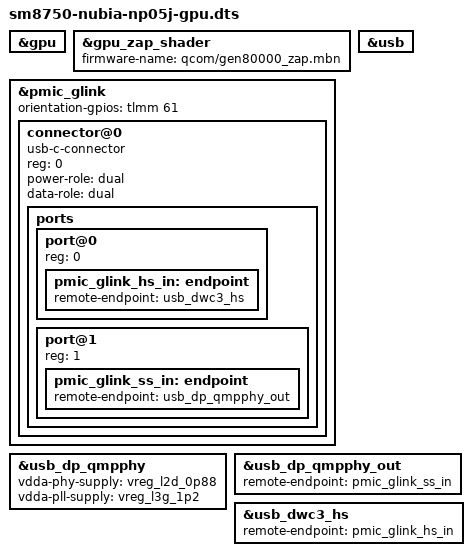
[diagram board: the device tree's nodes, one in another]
// SPDX-License-Identifier: BSD-3-Clause
/*
 * Copyright (c) 2026 Project Silicium / nubia NP05J (REDMAGIC Astra) bring-up
 *
 * Full Desktop Device Tree: Adreno 830v2 GPU (headless renderD128 คู่กับ UEFI GOP
 * simpledrm) + USB-C Dual-Role (OTG + USB 3.0 ผ่าน pmic-glink/ADSP) + Wi-Fi 7 + BT + Touch.
 */

/dts-v1/;

#include "sm8750-nubia-np05j-common.dtsi"

&gpu {
	status = "okay";
};

&gpu_zap_shader {
	firmware-name = "qcom/gen80000_zap.mbn";
};

&pmic_glink {
	orientation-gpios = <&tlmm 61 GPIO_ACTIVE_HIGH>;

	connector@0 {
		compatible = "usb-c-connector";
		reg = <0>;

		power-role = "dual";
		data-role = "dual";

		ports {
			#address-cells = <1>;
			#size-cells = <0>;

			port@0 {
				reg = <0>;

				pmic_glink_hs_in: endpoint {
					remote-endpoint = <&usb_dwc3_hs>;
				};
			};

			port@1 {
				reg = <1>;

				pmic_glink_ss_in: endpoint {
					remote-endpoint = <&usb_dp_qmpphy_out>;
				};
			};
		};
	};
};

&usb {
	status = "okay";
};

&usb_dp_qmpphy {
	vdda-phy-supply = <&vreg_l2d_0p88>;
	vdda-pll-supply = <&vreg_l3g_1p2>;

	status = "okay";
};

&usb_dp_qmpphy_out {
	remote-endpoint = <&pmic_glink_ss_in>;
};

&usb_dwc3_hs {
	remote-endpoint = <&pmic_glink_hs_in>;
};
